# alb32r003x register map
Vendor: ALB; Series: ALB RT SoC
ALB RealTime Control SoC using ALB RISC-V Core
CPU: ALB XF, little endian
Registers are 32-bit, access not given, reset 0x0 unless marked. A register's access mark holds for its fields unless they carry their own. Offsets are from the block's base; lines under a group give offsets from that group; [hi:lo] are bit positions; {n}, {i} and the like mark numbered series; 'fields as' and 'values as' point back to an identical list; <NAME> marks a mode.

## Memory map
0x20800000 ADCA_RESULT size 0x1F0
0x20800100 ADCA size 0xEA
0x20800200 ADCB_RESULT size 0x1F0
0x20800300 ADCB size 0xEA
0x20800400 ADCC_RESULT size 0x1F0
0x20800500 ADCC size 0xEA
{0x20FFFC00+0x400*n} EPWM{n} size 0x1FE (n=1..8)
0x21010000 EQEP1 size 0x70
0x21010400 EQEP2 size 0x70
0x21020000 ECAP1 size 0x6C
0x21020000 ECAP3 size 0x6C
0x21020400 ECAP2 size 0x6C
0x21030000 CMPSS1 size 0x60
0x21030400 CMPSS2 size 0x60
0x21030800 CMPSS3 size 0x60
0x21030C00 CMPSS4 size 0x60
0x21040000 DAC1 size 0xE — DAC: Digital-to-Analog Converter
0x21040400 DAC2 size 0xE
0x21050000 SDFM1 size 0x11C
0x21050400 SDFM2 size 0x11C
0x22000000 AES size 0x1000 — AES: Advanced Encryption Standard accelerator for secure data processing
0x22001000 CAN1 size 0xD1
0x22002000 CAN2 size 0xD1
0x23000000 EFLASHC size 0x10 — EFLASHC: Embedded Flash Controller managing on-chip program memory
0x23002000 DMA1_CH1 size 0x58
0x23002058 DMA1_CH2 size 0x58
0x230020B0 DMA1_CH3 size 0x58
0x23002108 DMA1_CH4 size 0x58
0x230022C0 DMA1_CTL_STA size 0x140
0x23003000 DMA2_CH1 size 0x58
0x23003058 DMA2_CH2 size 0x58
0x230030B0 DMA2_CH3 size 0x58
0x23003108 DMA2_CH4 size 0x58
0x230032C0 DMA2_CTL_STA size 0x140
0x23008000 XFLASHC size 0x400 — XFLASH control
0x23009000 SMCM size 0x100 — SMCM_R: Redundant Secure Memory Control Module for fault-tolerant access protection
0x24000000 TIMER1 size 0x1000 — TIMER1: General-purpose Timer 1 for timing, counting and PWM generation
0x24001000 TIMER2 size 0x1000
0x24002000 TIMER3 size 0x1000
0x24003000 TIMER4 size 0x1000
0x25000000 GPIO1 size 0x1000 — GPIO1: General-purpose I/O port 1 configurable as input, output, or alternate peripheral function
0x25001000 GPIO2 size 0x1000
0x25007000 GPIO3 size 0x1000
0x25008000 GPIO4 size 0x1000
0x25009000 GPIO5 size 0x1000
0x26000000 SPI1 size 0xF8
0x26001000 SPI2 size 0xF8
0x26002000 SPI3 size 0xF8
0x26003000 I2C3 size 0x124
0x27000000 LIN1 size 0x1000 — LIN1: Local Interconnect Network controller 1 for single-wire automotive serial communication
0x27001000 LIN2 size 0x1000
0x28000000 SCI1 size 0xD0
0x28001000 SCI2 size 0xD0
0x28002000 I2C1 size 0x124
0x28003000 I2C2 size 0x124
0x29000000 PWR size 0xC — PWR: power
0x29001000 SYSCTL size 0x980 — SYSCTL: System Control block for global device configuration, reset handling, and clock distribution management.
0x29002000 WDT1 size 0x1000 — WDT1: Independent Watchdog Timer 1 for fail-safe system reset on timeout
0x29003000 WWDG1 size 0x1000 — WWDG1: Windowed Watchdog Timer 1 for time-bounded application monitoring
0x2A000000 CLB1 blocks up to offset 0x2A0
0x2A000800 CLB2 blocks up to offset 0x2A0
0x2A001000 CLB3 blocks up to offset 0x2A0
0x2A001800 CLB4 blocks up to offset 0x2A0
0xE0020000 ECLIC size 0xFFFF — Enhanced Core Local Interrupt Controller
0xE0030000 MTIMER size 0x10000 — System Timer.

## Interrupts
1 SMCM — interrupt: Handles transfer events
1 SYSCTL — interrupt: Handles transfer events
1 WWDG1 — interrupt: Handles transfer events
90 TIMER1 — interrupt: Handles transfer events
99 EFLASHC — interrupt: Handles transfer events
100 XFLASHC — interrupt: Handles transfer events
112 GPIO1 — interrupt: Handles transfer events
114 AES — interrupt: Handles transfer events
158 LIN1 — interrupt: Handles transfer events
267 WDT1 — interrupt: Handles transfer events

## ECLIC — Enhanced Core Local Interrupt Controller
Base 0xE0020000
0x00 CLICCFG 8-bit rw
  [4:1] NLBITS
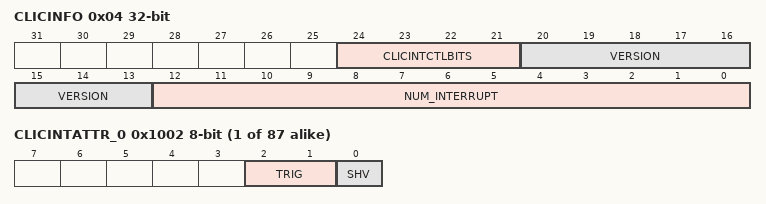
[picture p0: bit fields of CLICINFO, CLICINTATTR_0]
0x04 CLICINFO ro
  [24:21] CLICINTCTLBITS, [20:13] VERSION, [12:0] NUM_INTERRUPT
0x0B MTH 8-bit rw
{0x1000+4i} CLICINTIP_{i} 8-bit rw (i=0..84) — clicintip Register
  [0] IP
{0x1001+4i} CLICINTIE_{i} 8-bit rw (i=0..86) — clicintie Register
  [0] IE
{0x1002+4i} CLICINTATTR_{i} 8-bit rw (i=0..86) — clicintattr Register
  [2:1] TRIG, [0] SHV
{0x1003+4i} CLICINTCTL_{i} 8-bit rw (i=0..86) — clicintctl Register
  [7:0] LEVEL_PRIORITY
0x1158 CLICINTIP_85 8-bit rw — clicintip Register
  [0] IP
0x115C CLICINTIP_86 8-bit rw — clicintip Register
  [0] IP
